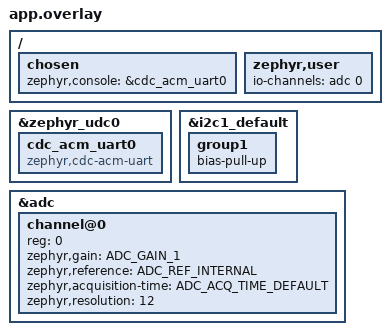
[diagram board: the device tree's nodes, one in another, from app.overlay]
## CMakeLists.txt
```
cmake_minimum_required(VERSION 3.20.0)
find_package(Zephyr REQUIRED HINTS $ENV{ZEPHYR_BASE})
project(sensor-node)

target_sources(app PRIVATE
  src/main.c
  src/handler_interface.c)

target_include_directories(app PRIVATE src)
```

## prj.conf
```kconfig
CONFIG_SERIAL=y
CONFIG_CONSOLE=y
CONFIG_UART_CONSOLE=y
CONFIG_UART_LINE_CTRL=y

CONFIG_USB_DEVICE_STACK=y
CONFIG_USB_DEVICE_PRODUCT="Sensor Node"
CONFIG_USB_CDC_ACM=y

CONFIG_I2C=y
CONFIG_I2C_TARGET=y

CONFIG_ADC=y
CONFIG_SENSOR=y
```

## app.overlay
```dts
#include <zephyr/dt-bindings/adc/adc.h>

/ {
	chosen {
		zephyr,console = &cdc_acm_uart0;
	};

	zephyr,user {
		io-channels = <&adc 0>;
	};
};

&zephyr_udc0 {
	cdc_acm_uart0: cdc_acm_uart0 {
		compatible = "zephyr,cdc-acm-uart";
	};
};

&i2c1_default {
	group1 {
		bias-pull-up;
	};
};

&adc {
	#address-cells = <1>;
	#size-cells = <0>;

	channel@0 {
		reg = <0>;
		zephyr,gain = "ADC_GAIN_1";
		zephyr,reference = "ADC_REF_INTERNAL";
		zephyr,acquisition-time = <ADC_ACQ_TIME_DEFAULT>;
		zephyr,resolution = <12>;
	};
};
```

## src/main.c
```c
#include <zephyr/kernel.h>
#include <zephyr/device.h>
#include <zephyr/drivers/uart.h>
#include <zephyr/usb/usb_device.h>
#include <zephyr/drivers/adc.h>
#include <zephyr/drivers/sensor.h>
#include <string.h>
#include <errno.h>

#include "handler_interface.h"

static const struct device *const console = DEVICE_DT_GET(DT_CHOSEN(zephyr_console));
static const struct device *const bus     = DEVICE_DT_GET(DT_NODELABEL(i2c1));

static const struct adc_dt_spec adc_chan =
	ADC_DT_SPEC_GET(DT_PATH(zephyr_user));

static struct sensor_value temp_value;

static int get_temp(struct sensor_value *out)
{
	int16_t sample;
	struct adc_sequence seq = {
		.buffer      = &sample,
		.buffer_size = sizeof(sample),
	};
	adc_sequence_init_dt(&adc_chan, &seq);

	int32_t raw_sum = 0;
	int good = 0;

	for (int i = 0; i < 16; i++) {
		if (adc_read_dt(&adc_chan, &seq) == 0) {
			raw_sum += sample;
			good++;
		}
	}

	if (good == 0) {
		return -EIO;
	}

	int32_t mv = raw_sum / good;
	adc_raw_to_millivolts_dt(&adc_chan, &mv);
	/* LMT85 at 3.3V supply: T(°C) = (1822 - V_mV) / 10.88 */
	int32_t temp_milli_c = (1822 - mv) * 10000 / 1088 * 10;

	out->val1 = temp_milli_c / 1000;
	out->val2 = (temp_milli_c % 1000) * 1000;
	return 0;
}

static int handle_read(uint8_t reg, uint8_t *out)
{
	uint8_t bytes[sizeof(struct sensor_value)];

	memcpy(bytes, &temp_value, sizeof(struct sensor_value));
	if (reg < (uint8_t)sizeof(struct sensor_value)) {
		*out = bytes[reg];
	}
	return 0;
}

static int handle_write(uint8_t reg, uint8_t val)
{
	return 0;
}

int main(void)
{
	uint32_t dtr = 0;

	if (usb_enable(NULL)) {
		return 0;
	}

	while (!dtr) {
		uart_line_ctrl_get(console, UART_LINE_CTRL_DTR, &dtr);
		k_sleep(K_MSEC(100));
	}

	if (!adc_is_ready_dt(&adc_chan)) {
		printk("ADC not ready\n");
		return 0;
	}

	if (adc_channel_setup_dt(&adc_chan) < 0) {
		printk("ADC channel setup failed\n");
		return 0;
	}

	handler_config_t cfg = {
		.handle_read  = handle_read,
		.handle_write = handle_write,
		.address      = 0x60,
	};

	int ret = register_target_with_handlers(bus, &cfg);

	if (ret != 0) {
		printk("i2c target register failed: %d\n", ret);
		return ret;
	}

	printk("Sensor node started\n");

	while (1) {
		if (get_temp(&temp_value) == 0) {
			printk("T=%d.%06d C\n", temp_value.val1, temp_value.val2);
		} else {
			printk("ADC read failed\n");
		}
		k_sleep(K_MSEC(1000));
	}

	return 0;
}
```

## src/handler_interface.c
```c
#include <zephyr/drivers/i2c.h>
#include "handler_interface.h"

static const handler_config_t *registered_config;
static struct i2c_target_config target_config;

typedef enum {
	COMM_IDLE,
	COMM_WRITE_REQUESTED,
	COMM_ADDR_RECEIVED,
} comm_state_t;

static struct {
	comm_state_t state;
	uint8_t addr;
} comm;

static int write_requested_cb(struct i2c_target_config *config)
{
	comm.state = COMM_WRITE_REQUESTED;
	return 0;
}

static int write_received_cb(struct i2c_target_config *config, uint8_t val)
{
	if (comm.state == COMM_WRITE_REQUESTED) {
		comm.addr = val;
		comm.state = COMM_ADDR_RECEIVED;
	} else {
		registered_config->handle_write(comm.addr, val);
		comm.addr++;
	}
	return 0;
}

static int read_requested_cb(struct i2c_target_config *config, uint8_t *out)
{
	if (comm.state == COMM_ADDR_RECEIVED) {
		registered_config->handle_read(comm.addr, out);
	} else {
		*out = 0;
	}
	return 0;
}

static int read_processed_cb(struct i2c_target_config *config, uint8_t *val)
{
	comm.addr++;
	registered_config->handle_read(comm.addr, val);
	return 0;
}

static int stop_cb(struct i2c_target_config *config)
{
	comm.state = COMM_IDLE;
	return 0;
}

static const struct i2c_target_callbacks handler_callbacks = {
	.write_requested = write_requested_cb,
	.read_requested  = read_requested_cb,
	.write_received  = write_received_cb,
	.read_processed  = read_processed_cb,
	.stop            = stop_cb,
};

int register_target_with_handlers(const struct device *bus, const handler_config_t *cfg)
{
	registered_config = cfg;
	target_config.address = cfg->address;
	target_config.callbacks = &handler_callbacks;
	return i2c_target_register(bus, &target_config);
}
```

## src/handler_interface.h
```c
#ifndef HANDLER_INTERFACE_H
#define HANDLER_INTERFACE_H

#include <zephyr/device.h>
#include <stdint.h>

typedef int (*handler_read_fn)(uint8_t reg, uint8_t *out);
typedef int (*handler_write_fn)(uint8_t reg, uint8_t val);

typedef struct {
	handler_read_fn handle_read;
	handler_write_fn handle_write;
	uint8_t address;
} handler_config_t;

int register_target_with_handlers(const struct device *bus, const handler_config_t *cfg);

#endif /* HANDLER_INTERFACE_H */
```
